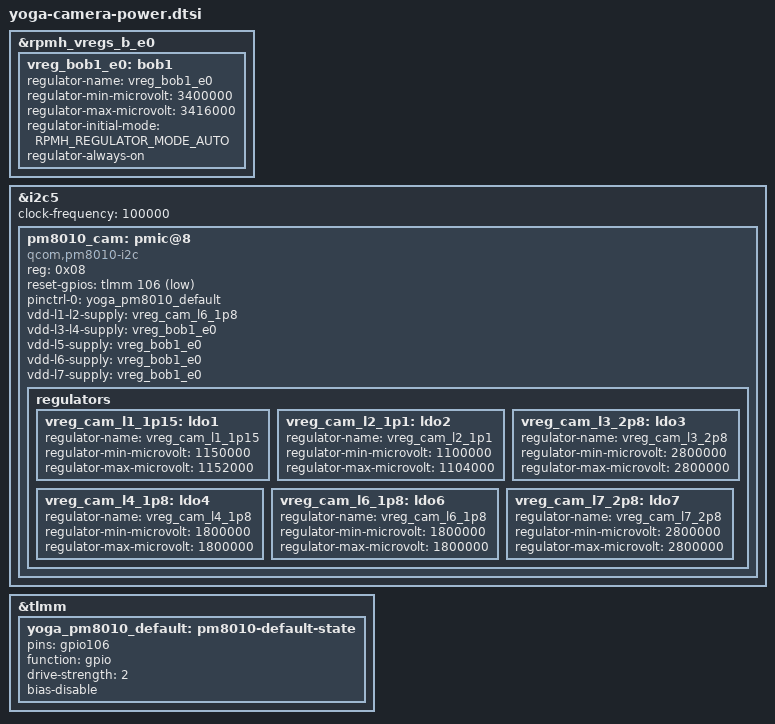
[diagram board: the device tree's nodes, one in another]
// SPDX-License-Identifier: BSD-3-Clause
/* Windows CAMF/CAMI rail votes; PM8010 supply cascade from Qualcomm CRD. */
&rpmh_vregs_b_e0 {
	vreg_bob1_e0: bob1 {
		regulator-name = "vreg_bob1_e0";
		regulator-min-microvolt = <3400000>;
		regulator-max-microvolt = <3416000>;
		regulator-initial-mode = <RPMH_REGULATOR_MODE_AUTO>;
		/* shortcut: PMIC driver has no input-power sequencing, keep on during bring-up. */
		regulator-always-on;
	};
};

&i2c5 {
	clock-frequency = <100000>;
	status = "okay";

	pm8010_cam: pmic@8 {
		compatible = "qcom,pm8010-i2c";
		reg = <0x08>;
		reset-gpios = <&tlmm 106 GPIO_ACTIVE_LOW>;
		pinctrl-0 = <&yoga_pm8010_default>;
		pinctrl-names = "default";
		vdd-l1-l2-supply = <&vreg_cam_l6_1p8>;
		vdd-l3-l4-supply = <&vreg_bob1_e0>;
		vdd-l5-supply = <&vreg_bob1_e0>;
		vdd-l6-supply = <&vreg_bob1_e0>;
		vdd-l7-supply = <&vreg_bob1_e0>;

		regulators {
			vreg_cam_l1_1p15: ldo1 {
				regulator-name = "vreg_cam_l1_1p15";
				regulator-min-microvolt = <1150000>;
				regulator-max-microvolt = <1152000>;
			};
			vreg_cam_l2_1p1: ldo2 {
				regulator-name = "vreg_cam_l2_1p1";
				regulator-min-microvolt = <1100000>;
				regulator-max-microvolt = <1104000>;
			};
			vreg_cam_l3_2p8: ldo3 {
				regulator-name = "vreg_cam_l3_2p8";
				regulator-min-microvolt = <2800000>;
				regulator-max-microvolt = <2800000>;
			};
			vreg_cam_l4_1p8: ldo4 {
				regulator-name = "vreg_cam_l4_1p8";
				regulator-min-microvolt = <1800000>;
				regulator-max-microvolt = <1800000>;
			};
			vreg_cam_l6_1p8: ldo6 {
				regulator-name = "vreg_cam_l6_1p8";
				regulator-min-microvolt = <1800000>;
				regulator-max-microvolt = <1800000>;
			};
			vreg_cam_l7_2p8: ldo7 {
				regulator-name = "vreg_cam_l7_2p8";
				regulator-min-microvolt = <2800000>;
				regulator-max-microvolt = <2800000>;
			};
		};
	};
};

&tlmm {
	yoga_pm8010_default: pm8010-default-state {
		pins = "gpio106";
		function = "gpio";
		drive-strength = <2>;
		bias-disable;
	};
};
